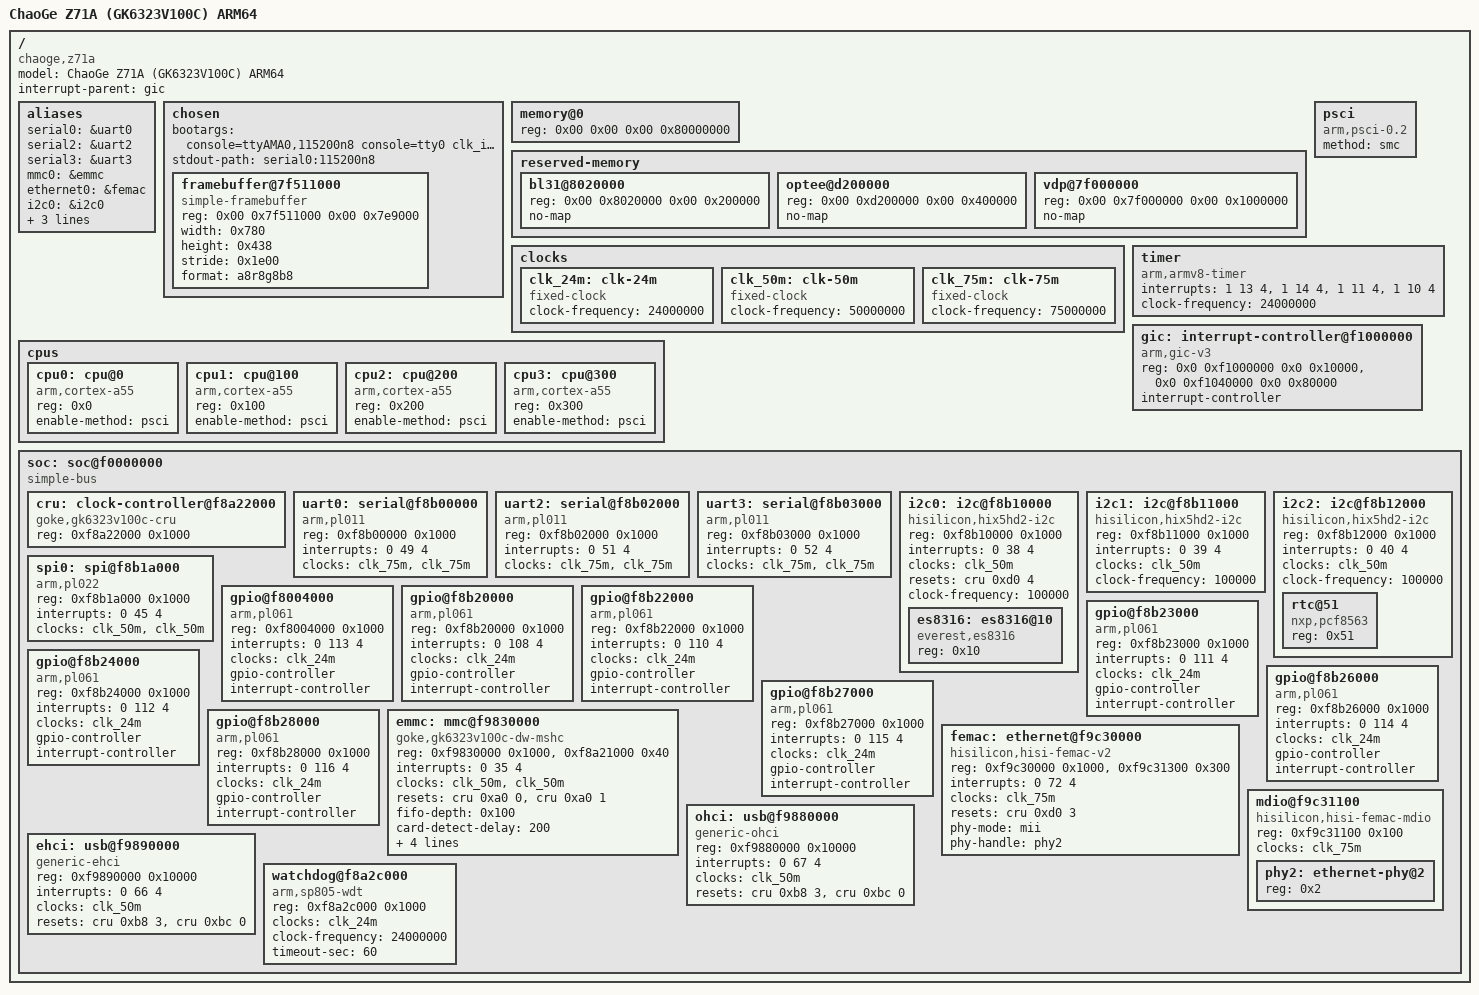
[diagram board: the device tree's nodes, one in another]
// SPDX-License-Identifier: GPL-2.0+
/*
 * 国科微 GK6323V100C（整机型号 ChaoGe Z71A）板级设备树
 *
 * 本文件不是照抄海思 Hi3798MV200H 的板级 dts，而是**逐项取自真机**：
 * 数据来源为运行中的原厂 Debian 内核导出的
 *   /sys/firmware/devicetree/base  →  real-devicetree.dts
 * 每一项地址、中断号、中断类型都与之对齐，没有臆造的参数。
 *
 * 与真机原树的差异：
 *   1) eMMC 的 compatible 追加 "snps,dw-mshc"，使主线的 dw_mmc-pltfm
 *      驱动能够认领（原 compatible "goke,gk6323v100c-dw-mshc" 是国科
 *      BSP 私有名，主线无此驱动）。
 *   2) 增加CRG时钟/复位控制器节点，主线GK6323 CRG最小驱动负责打开
 *      所有外设时钟门控和释放复位，保证网卡/USB/声卡正常工作。
 *   3) bootargs的 clk_ignore_unused 保持，避免时钟框架自动关闭未引用时钟。
 */

/dts-v1/;

/ {
	model = "ChaoGe Z71A (GK6323V100C) ARM64";
	compatible = "chaoge,z71a", "goke,gk6323v100c", "gk6323v100c-series";
	#address-cells = <2>;
	#size-cells = <2>;
	interrupt-parent = <&gic>;

	aliases {
		serial0 = &uart0;
		serial2 = &uart2;
		serial3 = &uart3;
		mmc0 = &emmc;
		ethernet0 = &femac;
		i2c0 = &i2c0;
		i2c1 = &i2c1;
		i2c2 = &i2c2;
		spi0 = &spi0;
	};

	chosen {
		/* 与 bootargs 分区完全一致，勿改；root= 亦由此下发 */
		bootargs = "console=ttyAMA0,115200n8 console=tty0 clk_ignore_unused net.ifnames=0 root=/dev/mmcblk0p18 rootfstype=ext4 rootwait rw panic=-1 blkdevparts=mmcblk0:1M(fastboot),512K(bootargs),512K(bootargsbak),20M(recovery),2M(deviceinfo),8M(securestore),2M(atf),8M(baseparam),8M(pqparam),2M(dtbo),10M(logo),10M(logobak),20M(fastplay),20M(recoverybak),60M(boot),20M(misc),20M(trustedcore),-(rootfs)";
		stdout-path = "serial0:115200n8";

		/* bootloader 已设好的线性帧缓冲，供内核接管控制台/启动画面 */
		framebuffer@7f511000 {
			compatible = "simple-framebuffer";
			reg = <0x00 0x7f511000 0x00 0x7e9000>;
			width = <0x780>;
			height = <0x438>;
			stride = <0x1e00>;
			format = "a8r8g8b8";
			status = "okay";
		};
	};

	memory@0 {
		device_type = "memory";
		reg = <0x00 0x00 0x00 0x80000000>;
	};

	reserved-memory {
		#address-cells = <2>;
		#size-cells = <2>;
		ranges;

		bl31@8020000 {
			reg = <0x00 0x8020000 0x00 0x200000>;
			no-map;
		};

		optee@d200000 {
			reg = <0x00 0xd200000 0x00 0x400000>;
			no-map;
		};

		vdp@7f000000 {
			reg = <0x00 0x7f000000 0x00 0x1000000>;
			no-map;
		};
	};

	clocks {
		clk_24m: clk-24m {
			compatible = "fixed-clock";
			#clock-cells = <0>;
			clock-frequency = <24000000>;
		};

		clk_50m: clk-50m {
			compatible = "fixed-clock";
			#clock-cells = <0>;
			clock-frequency = <50000000>;
		};

		clk_75m: clk-75m {
			compatible = "fixed-clock";
			#clock-cells = <0>;
			clock-frequency = <75000000>;
		};
	};

	cpus {
		#address-cells = <1>;
		#size-cells = <0>;

		cpu0: cpu@0 {
			device_type = "cpu";
			compatible = "arm,cortex-a55";
			reg = <0x0>;
			enable-method = "psci";
		};

		cpu1: cpu@100 {
			device_type = "cpu";
			compatible = "arm,cortex-a55";
			reg = <0x100>;
			enable-method = "psci";
		};

		cpu2: cpu@200 {
			device_type = "cpu";
			compatible = "arm,cortex-a55";
			reg = <0x200>;
			enable-method = "psci";
		};

		cpu3: cpu@300 {
			device_type = "cpu";
			compatible = "arm,cortex-a55";
			reg = <0x300>;
			enable-method = "psci";
		};
	};

	psci {
		compatible = "arm,psci-0.2";
		method = "smc";
	};

	/* A55 的 arch timer：4 个 PPI，频率 24MHz（与真机一致） */
	timer {
		compatible = "arm,armv8-timer";
		interrupts = <1 13 4>, <1 14 4>, <1 11 4>, <1 10 4>;
		clock-frequency = <24000000>;
	};

	gic: interrupt-controller@f1000000 {
		compatible = "arm,gic-v3";
		reg = <0x0 0xf1000000 0x0 0x10000>,
		      <0x0 0xf1040000 0x0 0x80000>;
		interrupt-controller;
		#interrupt-cells = <3>;
	};

	soc: soc@f0000000 {
		#address-cells = <1>;
		#size-cells = <1>;
		compatible = "simple-bus";
		ranges = <0xf0000000 0x0 0xf0000000 0x10000000>;

		/* GK6323V100C CRG 时钟/复位控制器 - 最小驱动匹配此节点 */
		cru: clock-controller@f8a22000 {
			compatible = "goke,gk6323v100c-cru";
			reg = <0xf8a22000 0x1000>;
			#clock-cells = <1>;
			#reset-cells = <2>;
		};

		uart0: serial@f8b00000 {
			compatible = "arm,pl011", "arm,primecell";
			reg = <0xf8b00000 0x1000>;
			interrupts = <0 49 4>;
			clocks = <&clk_75m>, <&clk_75m>;
			clock-names = "uartclk", "apb_pclk";
			status = "okay";
		};

		uart2: serial@f8b02000 {
			compatible = "arm,pl011", "arm,primecell";
			reg = <0xf8b02000 0x1000>;
			interrupts = <0 51 4>;
			clocks = <&clk_75m>, <&clk_75m>;
			clock-names = "uartclk", "apb_pclk";
			status = "okay";
		};

		uart3: serial@f8b03000 {
			compatible = "arm,pl011", "arm,primecell";
			reg = <0xf8b03000 0x1000>;
			interrupts = <0 52 4>;
			clocks = <&clk_75m>, <&clk_75m>;
			clock-names = "uartclk", "apb_pclk";
			status = "okay";
		};

		i2c0: i2c@f8b10000 {
			compatible = "hisilicon,hix5hd2-i2c";
			reg = <0xf8b10000 0x1000>;
			interrupts = <0 38 4>;
			clocks = <&clk_50m>;
			resets = <&cru 0xd0 4>;
			clock-names = "apb_pclk";
			clock-frequency = <100000>;
			#address-cells = <1>;
			#size-cells = <0>;
			status = "okay";

			es8316: es8316@10 {
				compatible = "everest,es8316";
				reg = <0x10>;
				#sound-dai-cells = <0>;
				status = "okay";
			};
		};

		i2c1: i2c@f8b11000 {
			compatible = "hisilicon,hix5hd2-i2c";
			reg = <0xf8b11000 0x1000>;
			interrupts = <0 39 4>;
			clocks = <&clk_50m>;
			clock-names = "apb_pclk";
			clock-frequency = <100000>;
			#address-cells = <1>;
			#size-cells = <0>;
			status = "okay";
		};

		i2c2: i2c@f8b12000 {
			compatible = "hisilicon,hix5hd2-i2c";
			reg = <0xf8b12000 0x1000>;
			interrupts = <0 40 4>;
			clocks = <&clk_50m>;
			clock-names = "apb_pclk";
			clock-frequency = <100000>;
			#address-cells = <1>;
			#size-cells = <0>;
			status = "okay";

			rtc@51 {
				compatible = "nxp,pcf8563";
				reg = <0x51>;
				status = "okay";
			};
		};

		spi0: spi@f8b1a000 {
			compatible = "arm,pl022", "arm,primecell";
			reg = <0xf8b1a000 0x1000>;
			interrupts = <0 45 4>;
			clocks = <&clk_50m>, <&clk_50m>;
			clock-names = "sspclk", "apb_pclk";
			#address-cells = <1>;
			#size-cells = <0>;
			status = "okay";
		};

		gpio@f8004000 {
			compatible = "arm,pl061", "arm,primecell";
			reg = <0xf8004000 0x1000>;
			interrupts = <0 113 4>;
			clocks = <&clk_24m>;
			clock-names = "apb_pclk";
			gpio-controller;
			#gpio-cells = <2>;
			interrupt-controller;
			#interrupt-cells = <2>;
		};

		gpio@f8b20000 {
			compatible = "arm,pl061", "arm,primecell";
			reg = <0xf8b20000 0x1000>;
			interrupts = <0 108 4>;
			clocks = <&clk_24m>;
			clock-names = "apb_pclk";
			gpio-controller;
			#gpio-cells = <2>;
			interrupt-controller;
			#interrupt-cells = <2>;
		};

		gpio@f8b22000 {
			compatible = "arm,pl061", "arm,primecell";
			reg = <0xf8b22000 0x1000>;
			interrupts = <0 110 4>;
			clocks = <&clk_24m>;
			clock-names = "apb_pclk";
			gpio-controller;
			#gpio-cells = <2>;
			interrupt-controller;
			#interrupt-cells = <2>;
		};

		gpio@f8b23000 {
			compatible = "arm,pl061", "arm,primecell";
			reg = <0xf8b23000 0x1000>;
			interrupts = <0 111 4>;
			clocks = <&clk_24m>;
			clock-names = "apb_pclk";
			gpio-controller;
			#gpio-cells = <2>;
			interrupt-controller;
			#interrupt-cells = <2>;
		};

		gpio@f8b24000 {
			compatible = "arm,pl061", "arm,primecell";
			reg = <0xf8b24000 0x1000>;
			interrupts = <0 112 4>;
			clocks = <&clk_24m>;
			clock-names = "apb_pclk";
			gpio-controller;
			#gpio-cells = <2>;
			interrupt-controller;
			#interrupt-cells = <2>;
		};

		gpio@f8b26000 {
			compatible = "arm,pl061", "arm,primecell";
			reg = <0xf8b26000 0x1000>;
			interrupts = <0 114 4>;
			clocks = <&clk_24m>;
			clock-names = "apb_pclk";
			gpio-controller;
			#gpio-cells = <2>;
			interrupt-controller;
			#interrupt-cells = <2>;
		};

		gpio@f8b27000 {
			compatible = "arm,pl061", "arm,primecell";
			reg = <0xf8b27000 0x1000>;
			interrupts = <0 115 4>;
			clocks = <&clk_24m>;
			clock-names = "apb_pclk";
			gpio-controller;
			#gpio-cells = <2>;
			interrupt-controller;
			#interrupt-cells = <2>;
		};

		gpio@f8b28000 {
			compatible = "arm,pl061", "arm,primecell";
			reg = <0xf8b28000 0x1000>;
			interrupts = <0 116 4>;
			clocks = <&clk_24m>;
			clock-names = "apb_pclk";
			gpio-controller;
			#gpio-cells = <2>;
			interrupt-controller;
			#interrupt-cells = <2>;
		};

		/*
		 * eMMC：根文件系统在 mmcblk0p18，这一项必须起来。
		 * compatible 追加 "snps,dw-mshc" 让主线 dw_mmc-pltfm 认领；
		 * biu/ciu 指向 fixed-clock，CRG驱动会直接开门控保证时钟可用。
		 */
		emmc: mmc@f9830000 {
			compatible = "goke,gk6323v100c-dw-mshc", "snps,dw-mshc";
			reg = <0xf9830000 0x1000>, <0xf8a21000 0x40>;
			interrupts = <0 35 4>;
			clocks = <&clk_50m>, <&clk_50m>;
			resets = <&cru 0xa0 0>, <&cru 0xa0 1>;
			reset-names = "reset", "reset-hold";
			clock-names = "biu", "ciu";
			fifo-depth = <0x100>;
			card-detect-delay = <200>;
			bus-width = <8>;
			non-removable;
			mmc-ddr-1_8v;
			disable-wp;
			status = "okay";
		};

		/*
		 * 板载百兆网口：compatible 取真机原值 "hisilicon,hisi-femac-v2"。
		 * CRG驱动负责打开总线/MAC/MDIO时钟，释放FEMAC复位和PHY时钟。
		 */
		femac: ethernet@f9c30000 {
			compatible = "hisilicon,hisi-femac-v2";
			reg = <0xf9c30000 0x1000>, <0xf9c31300 0x300>;
			interrupts = <0 72 4>;
			clocks = <&clk_75m>;
			resets = <&cru 0xd0 3>;
			reset-names = "mac";
			phy-mode = "mii";
			phy-handle = <&phy2>;
			status = "okay";
		};

		mdio@f9c31100 {
			compatible = "hisilicon,hisi-femac-mdio";
			reg = <0xf9c31100 0x100>;
			clocks = <&clk_75m>;
			#address-cells = <1>;
			#size-cells = <0>;

			phy2: ethernet-phy@2 {
				reg = <0x2>;
			};
		};

		/* USB2.0：EHCI/OHCI控制器，CRG驱动负责打开时钟释放复位 */
		ohci: usb@f9880000 {
			compatible = "generic-ohci";
			reg = <0xf9880000 0x10000>;
			interrupts = <0 67 4>;
			clocks = <&clk_50m>;
			resets = <&cru 0xb8 3>, <&cru 0xbc 0>;
			status = "okay";
		};

		ehci: usb@f9890000 {
			compatible = "generic-ehci";
			reg = <0xf9890000 0x10000>;
			interrupts = <0 66 4>;
			clocks = <&clk_50m>;
			resets = <&cru 0xb8 3>, <&cru 0xbc 0>;
			status = "okay";
		};

		/* SP805 看门狗，同时是这颗 SoC 的复位通道（panic 后靠它重启） */
		watchdog@f8a2c000 {
			compatible = "arm,sp805-wdt", "arm,primecell";
			reg = <0xf8a2c000 0x1000>;
			clocks = <&clk_24m>;
			clock-names = "apb_pclk";
			clock-frequency = <24000000>;
			timeout-sec = <60>;
			status = "okay";
		};
	};
};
